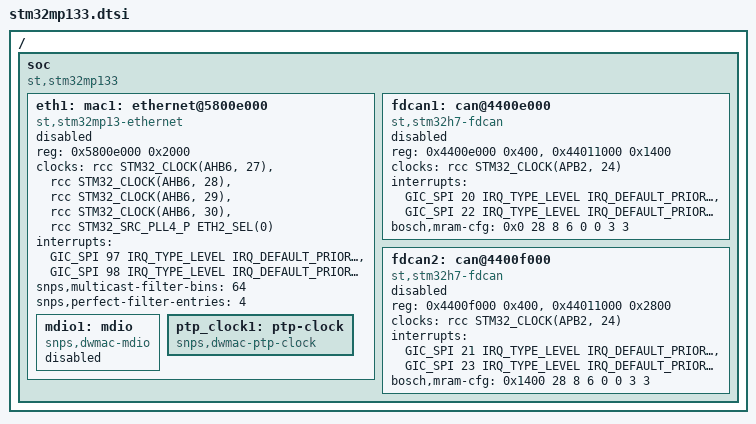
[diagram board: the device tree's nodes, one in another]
/*
 * Copyright (c) 2026 STMicroelectronics
 *
 * SPDX-License-Identifier: Apache-2.0
 */

#include <st/mp13/stm32mp13.dtsi>

/ {
	soc {
		compatible = "st,stm32mp133", "st,stm32mp13", "simple-bus";

		eth1: mac1: ethernet@5800e000 {
			compatible = "st,stm32mp13-ethernet", "st,stm32h7-ethernet",
				     "st,stm32-ethernet", "snps,dwmac";
			reg = <0x5800e000 0x2000>;
			clock-names = "stm-eth", "mac-clk", "mac-clk-tx", "mac-clk-rx", "eth-ker";
			clocks = <&rcc STM32_CLOCK(AHB6, 27)>,
				 <&rcc STM32_CLOCK(AHB6, 28)>,
				 <&rcc STM32_CLOCK(AHB6, 29)>,
				 <&rcc STM32_CLOCK(AHB6, 30)>,
				 <&rcc STM32_SRC_PLL4_P ETH2_SEL(0)>;
			interrupts = <GIC_SPI 97 IRQ_TYPE_LEVEL IRQ_DEFAULT_PRIORITY>,
				     <GIC_SPI 98 IRQ_TYPE_LEVEL IRQ_DEFAULT_PRIORITY>;
			snps,multicast-filter-bins = <64>;
			snps,perfect-filter-entries = <4>;
			status = "disabled";

			mdio1: mdio {
				compatible = "snps,dwmac-mdio";
				#address-cells = <1>;
				#size-cells = <0>;
				status = "disabled";
			};

			ptp_clock1: ptp-clock {
				compatible = "snps,dwmac-ptp-clock";
			};
		};

		fdcan1: can@4400e000 {
			compatible = "st,stm32h7-fdcan";
			reg = <0x4400e000 0x400>, <0x44011000 0x1400>;
			reg-names = "m_can", "message_ram";
			clocks = <&rcc STM32_CLOCK(APB2, 24)>;
			interrupts = <GIC_SPI 20 IRQ_TYPE_LEVEL IRQ_DEFAULT_PRIORITY>,
				     <GIC_SPI 22 IRQ_TYPE_LEVEL IRQ_DEFAULT_PRIORITY>;
			interrupt-names = "int0", "int1";
			bosch,mram-cfg = <0x0 28 8 6 0 0 3 3>;
			status = "disabled";
		};

		fdcan2: can@4400f000 {
			compatible = "st,stm32h7-fdcan";
			reg = <0x4400f000 0x400>, <0x44011000 0x2800>;
			reg-names = "m_can", "message_ram";
			clocks = <&rcc STM32_CLOCK(APB2, 24)>;
			interrupts = <GIC_SPI 21 IRQ_TYPE_LEVEL IRQ_DEFAULT_PRIORITY>,
				     <GIC_SPI 23 IRQ_TYPE_LEVEL IRQ_DEFAULT_PRIORITY>;
			interrupt-names = "int0", "int1";
			bosch,mram-cfg = <0x1400 28 8 6 0 0 3 3>;
			status = "disabled";
		};
	};
};
